# ATSAMRH71F20C register map
Vendor: Microchip Technology; Series: SAMRH71; File version: 0
CPU: CM7 r1p1, little endian, MPU, FPU, double-precision FPU, I-cache, D-cache, ITCM, DTCM, 3 interrupt priority bits, 75 interrupts
Registers are 32-bit, read-write, reset 0x0 unless marked. A register's access mark holds for its fields unless they carry their own. Offsets are from the block's base; [hi:lo] are bit positions; {n}, {i} and the like mark numbered series.

## FPU — Floating Point Unit
Base 0xE000EF30
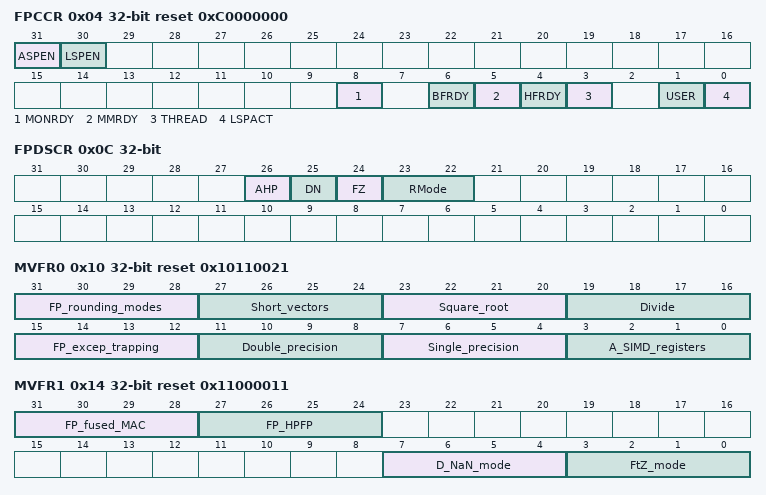
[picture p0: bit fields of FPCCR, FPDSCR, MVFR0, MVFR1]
0x04 FPCCR reset 0xC0000000 — Floating-point Context Control Register
  [31] ASPEN — Enables CONTROL.FPCA setting on execution of a floating-point instruction. This results in automatic hardware state preservation and restoration, for floating-point context, on exception entry and exit.
  [30] LSPEN — Enable automatic lazy state preservation for floating-point context.
  [8] MONRDY — DebugMonitor is enabled and priority permits setting MON_PEND when the floating-point stack frame was allocated.
  [6] BFRDY — BusFault is enabled and priority permitted setting the BusFault handler to the pending state when the floating-point stack frame was allocated.
  [5] MMRDY — MemManage is enabled and priority permitted setting the MemManage handler to the pending state when the floating-point stack frame was allocated.
  [4] HFRDY — Priority permitted setting the HardFault handler to the pending state when the floating-point stack frame was allocated.
  [3] THREAD — Mode was Thread Mode when the floating-point stack frame was allocated.
  [1] USER — Privilege level was user when the floating-point stack frame was allocated.
  [0] LSPACT — Lazy state preservation is active. Floating-point stack frame has been allocated but saving state to it has been deferred.
0x08 FPCAR — Floating-point Context Address Register
  [31:3] ADDRESS — The location of the unpopulated floating-point register space allocated on an exception stack frame.
0x0C FPDSCR — Floating-point Default Status Control Register
  [26] AHP — Default value for FPSCR.AHP.
  [25] DN — Default value for FPSCR.DN.
  [24] FZ — Default value for FPSCR.FZ.
  [23:22] RMode — Default value for FPSCR.RMode.
0x10 MVFR0 ro reset 0x10110021 — Media and VFP Feature Register 0
  [31:28] FP_rounding_modes — Indicates the rounding modes supported by the FP floating-point hardware
  [27:24] Short_vectors — Indicates the hardware support for FP short vectors
  [23:20] Square_root — Indicates the hardware support for FP square root operations
  [19:16] Divide — Indicates the hardware support for FP divide operations
  [15:12] FP_excep_trapping — Indicates whether the FP hardware implementation supports exception trapping
  [11:8] Double_precision — Indicates the hardware support for FP double-precision operations
  [7:4] Single_precision — Indicates the hardware support for FP single-precision operations
  [3:0] A_SIMD_registers — Indicates the size of the FP register bank
0x14 MVFR1 ro reset 0x11000011 — Media and VFP Feature Register 1
  [31:28] FP_fused_MAC — Indicates whether the FP supports fused multiply accumulate operations
  [27:24] FP_HPFP — Floating Point Half-Precision and double-precision
  [7:4] D_NaN_mode — Indicates whether the FP hardware implementation supports only the Default NaN mode
  [3:0] FtZ_mode — Indicates whether the FP hardware implementation supports only the Flush-to-Zero mode of operation
0x18 MVFR2 ro reset 0x40 — Media and VFP Feature Register 2
  [7:4] VFP_Misc — Indicates the hardware support for FP miscellaneous features

## ITM — Instrumentation Trace Macrocell
Base 0xE0000000
{0x0+4i} PORT_BYTE_MODE[{i}] (i=0..31) wo — ITM Stimulus Port Registers
  [7:0] PORT
{0x0+4i} PORT_HWORD_MODE[{i}] (i=0..31) wo (alternate view of PORT_BYTE_MODE[{i}]) — ITM Stimulus Port Registers
  [15:0] PORT
{0x0+4i} PORT_WORD_MODE[{i}] (i=0..31) wo (alternate view of PORT_BYTE_MODE[{i}]) — ITM Stimulus Port Registers
  [31:0] PORT
0xE00 TER — ITM Trace Enable Register
0xE40 TPR — ITM Trace Privilege Register
  [3:0] PRIVMASK
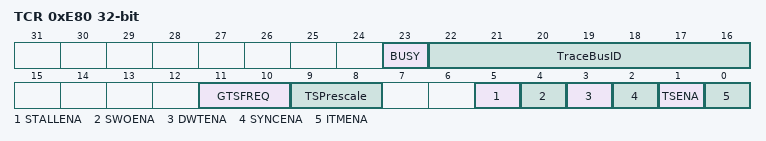
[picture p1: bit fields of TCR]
0xE80 TCR — ITM Trace Control Register
  [23] BUSY, [22:16] TraceBusID, [11:10] GTSFREQ, [9:8] TSPrescale, [5] STALLENA, [4] SWOENA, [3] DWTENA, [2] SYNCENA, [1] TSENA, [0] ITMENA
